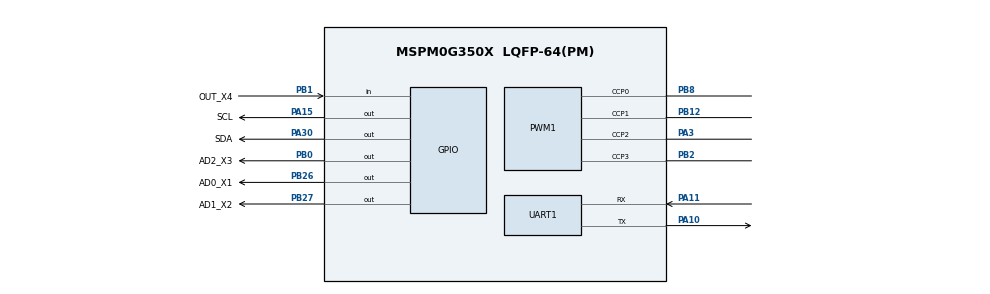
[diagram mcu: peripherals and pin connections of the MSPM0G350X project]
/**
 * @cliArgs --device "MSPM0G350X" --part "Default" --package "LQFP-64(PM)" --product "mspm0_sdk@2.02.00.05"
 * @versions {"tool":"1.21.1+3772"}
 */

/**
 * Import the modules used in this configuration.
 */
const GPIO    = scripting.addModule("/ti/driverlib/GPIO", {}, false);
const GPIO1   = GPIO.addInstance();
const GPIO2   = GPIO.addInstance();
const GPIO3   = GPIO.addInstance();
const GPIO4   = GPIO.addInstance();
const GPIO5   = GPIO.addInstance();
const GPIO6   = GPIO.addInstance();
const PWM     = scripting.addModule("/ti/driverlib/PWM", {}, false);
const PWM1    = PWM.addInstance();
const SYSCTL  = scripting.addModule("/ti/driverlib/SYSCTL");
const SYSTICK = scripting.addModule("/ti/driverlib/SYSTICK");
const TIMER   = scripting.addModule("/ti/driverlib/TIMER", {}, false);
const TIMER1  = TIMER.addInstance();
const TIMER2  = TIMER.addInstance();
const UART    = scripting.addModule("/ti/driverlib/UART", {}, false);
const UART1   = UART.addInstance();

/**
 * Write custom configuration values to the imported modules.
 */
const divider7       = system.clockTree["PLL_PDIV"];
divider7.divideValue = 2;

const divider9       = system.clockTree["UDIV"];
divider9.divideValue = 2;

const gate7  = system.clockTree["MFCLKGATE"];
gate7.enable = true;

const multiplier2         = system.clockTree["PLL_QDIV"];
multiplier2.multiplyValue = 8;

const mux4       = system.clockTree["EXHFMUX"];
mux4.inputSelect = "EXHFMUX_XTAL";

const mux8       = system.clockTree["HSCLKMUX"];
mux8.inputSelect = "HSCLKMUX_SYSPLL0";

const mux12       = system.clockTree["SYSPLLMUX"];
mux12.inputSelect = "zSYSPLLMUX_HFCLK";

const pinFunction4        = system.clockTree["HFXT"];
pinFunction4.inputFreq    = 40;
pinFunction4.enable       = true;
pinFunction4.HFCLKMonitor = true;
pinFunction4.HFXTStartup  = 100;

GPIO1.$name                              = "LED";
GPIO1.port                               = "PORTA";
GPIO1.associatedPins[0].internalResistor = "PULL_DOWN";
GPIO1.associatedPins[0].assignedPin      = "17";
GPIO1.associatedPins[0].$name            = "MCU";

const Board = scripting.addModule("/ti/driverlib/Board", {}, false);

GPIO2.$name                         = "BEEP";
GPIO2.port                          = "PORTB";
GPIO2.associatedPins[0].assignedPin = "5";
GPIO2.associatedPins[0].$name       = "OUT";

GPIO3.$name                          = "OLED";
GPIO3.port                           = "PORTA";
GPIO3.associatedPins.create(2);
GPIO3.associatedPins[0].$name        = "SCL";
GPIO3.associatedPins[0].initialValue = "SET";
GPIO3.associatedPins[0].assignedPin  = "15";
GPIO3.associatedPins[0].pin.$assign  = "PA15";
GPIO3.associatedPins[1].$name        = "SDA";
GPIO3.associatedPins[1].initialValue = "SET";
GPIO3.associatedPins[1].assignedPin  = "30";
GPIO3.associatedPins[1].pin.$assign  = "PA30";

GPIO4.$name                               = "GPIO_ENCODER_L";
GPIO4.associatedPins.create(2);
GPIO4.associatedPins[0].direction         = "INPUT";
GPIO4.associatedPins[0].assignedPort      = "PORTB";
GPIO4.associatedPins[0].$name             = "H1A";
GPIO4.associatedPins[0].assignedPin       = "21";
GPIO4.associatedPins[0].polarity          = "RISE";
GPIO4.associatedPins[0].interruptEn       = true;
GPIO4.associatedPins[0].interruptPriority = "0";
GPIO4.associatedPins[1].direction         = "INPUT";
GPIO4.associatedPins[1].assignedPort      = "PORTB";
GPIO4.associatedPins[1].$name             = "H1B";
GPIO4.associatedPins[1].assignedPin       = "22";
GPIO4.associatedPins[1].polarity          = "RISE";
GPIO4.associatedPins[1].interruptEn       = true;
GPIO4.associatedPins[1].interruptPriority = "0";

GPIO5.$name                               = "GPIO_ENCODER_R";
GPIO5.associatedPins.create(2);
GPIO5.associatedPins[0].$name             = "H2A";
GPIO5.associatedPins[0].direction         = "INPUT";
GPIO5.associatedPins[0].assignedPort      = "PORTB";
GPIO5.associatedPins[0].assignedPin       = "13";
GPIO5.associatedPins[0].polarity          = "RISE";
GPIO5.associatedPins[0].interruptEn       = true;
GPIO5.associatedPins[0].interruptPriority = "0";
GPIO5.associatedPins[1].$name             = "H2B";
GPIO5.associatedPins[1].direction         = "INPUT";
GPIO5.associatedPins[1].assignedPort      = "PORTA";
GPIO5.associatedPins[1].assignedPin       = "31";
GPIO5.associatedPins[1].interruptEn       = true;
GPIO5.associatedPins[1].polarity          = "RISE";
GPIO5.associatedPins[1].interruptPriority = "0";

GPIO6.$name                              = "Eight_IR";
GPIO6.associatedPins.create(4);
GPIO6.associatedPins[0].$name            = "AD0_X1";
GPIO6.associatedPins[0].pin.$assign      = "PB26";
GPIO6.associatedPins[1].$name            = "AD1_X2";
GPIO6.associatedPins[1].pin.$assign      = "PB27";
GPIO6.associatedPins[2].$name            = "AD2_X3";
GPIO6.associatedPins[2].pin.$assign      = "PB0";
GPIO6.associatedPins[3].$name            = "OUT_X4";
GPIO6.associatedPins[3].direction        = "INPUT";
GPIO6.associatedPins[3].internalResistor = "PULL_UP";
GPIO6.associatedPins[3].pin.$assign      = "PB1";

PWM1.$name                              = "motor_PWM";
PWM1.clockDivider                       = 2;
PWM1.ccIndex                            = [0,1,2,3];
PWM1.peripheral.ccp0Pin.$assign         = "PB8";
PWM1.peripheral.ccp1Pin.$assign         = "PB12";
PWM1.peripheral.ccp2Pin.$assign         = "PA3";
PWM1.peripheral.ccp3Pin.$assign         = "PB2";
PWM1.PWM_CHANNEL_0.$name                = "ti_driverlib_pwm_PWMTimerCC0";
PWM1.PWM_CHANNEL_1.$name                = "ti_driverlib_pwm_PWMTimerCC1";
PWM1.ccp0PinConfig.direction            = scripting.forceWrite("OUTPUT");
PWM1.ccp0PinConfig.hideOutputInversion  = scripting.forceWrite(false);
PWM1.ccp0PinConfig.onlyInternalResistor = scripting.forceWrite(false);
PWM1.ccp0PinConfig.passedPeripheralType = scripting.forceWrite("Digital");
PWM1.ccp0PinConfig.$name                = "ti_driverlib_gpio_GPIOPinGeneric2";
PWM1.ccp1PinConfig.direction            = scripting.forceWrite("OUTPUT");
PWM1.ccp1PinConfig.hideOutputInversion  = scripting.forceWrite(false);
PWM1.ccp1PinConfig.onlyInternalResistor = scripting.forceWrite(false);
PWM1.ccp1PinConfig.passedPeripheralType = scripting.forceWrite("Digital");
PWM1.ccp1PinConfig.$name                = "ti_driverlib_gpio_GPIOPinGeneric3";
PWM1.PWM_CHANNEL_2.$name                = "ti_driverlib_pwm_PWMTimerCC2";
PWM1.PWM_CHANNEL_3.$name                = "ti_driverlib_pwm_PWMTimerCC3";
PWM1.ccp2PinConfig.$name                = "ti_driverlib_gpio_GPIOPinGeneric4";
PWM1.ccp3PinConfig.$name                = "ti_driverlib_gpio_GPIOPinGeneric5";

SYSCTL.forceDefaultClkConfig = true;
SYSCTL.clockTreeEn           = true;
SYSCTL.validateClkStatus     = true;

SYSTICK.periodEnable      = true;
SYSTICK.systickEnable     = true;
SYSTICK.interruptPriority = "0";
SYSTICK.period            = 80;

TIMER1.$name              = "TIMER_20ms";
TIMER1.timerPeriod        = "20 ms";
TIMER1.timerClkDiv        = 8;
TIMER1.timerClkPrescale   = 10;
TIMER1.timerMode          = "PERIODIC";
TIMER1.interrupts         = ["ZERO"];
TIMER1.interruptPriority  = "1";
TIMER1.peripheral.$assign = "TIMG6";

TIMER2.$name              = "TIMER_DISPLAY";
TIMER2.timerMode          = "PERIODIC";
TIMER2.timerClkDiv        = 8;
TIMER2.timerClkPrescale   = 125;
TIMER2.interrupts         = ["ZERO"];
TIMER2.interruptPriority  = "2";
TIMER2.timerPeriod        = "50ms";
TIMER2.peripheral.$assign = "TIMA1";

UART1.$name                    = "UART_0";
UART1.targetBaudRate           = 115200;
UART1.enabledInterrupts        = ["RX","RX_TIMEOUT_ERROR"];
UART1.rxFifoThreshold          = "DL_UART_RX_FIFO_LEVEL_ONE_ENTRY";
UART1.rxTimeoutValue           = 15;
UART1.uartClkDiv               = "4";
UART1.peripheral.$assign       = "UART0";
UART1.peripheral.rxPin.$assign = "PA11";
UART1.peripheral.txPin.$assign = "PA10";
UART1.txPinConfig.$name        = "ti_driverlib_gpio_GPIOPinGeneric0";
UART1.rxPinConfig.$name        = "ti_driverlib_gpio_GPIOPinGeneric1";

/**
 * Pinmux solution for unlocked pins/peripherals. This ensures that minor changes to the automatic solver in a future
 * version of the tool will not impact the pinmux you originally saw.  These lines can be completely deleted in order to
 * re-solve from scratch.
 */
pinFunction4.peripheral.$suggestSolution           = "SYSCTL";
pinFunction4.peripheral.hfxInPin.$suggestSolution  = "PA5";
pinFunction4.peripheral.hfxOutPin.$suggestSolution = "PA6";
GPIO1.associatedPins[0].pin.$suggestSolution       = "PA17";
Board.peripheral.$suggestSolution                  = "DEBUGSS";
Board.peripheral.swclkPin.$suggestSolution         = "PA20";
Board.peripheral.swdioPin.$suggestSolution         = "PA19";
GPIO2.associatedPins[0].pin.$suggestSolution       = "PB5";
GPIO4.associatedPins[0].pin.$suggestSolution       = "PB21";
GPIO4.associatedPins[1].pin.$suggestSolution       = "PB22";
GPIO5.associatedPins[0].pin.$suggestSolution       = "PB13";
GPIO5.associatedPins[1].pin.$suggestSolution       = "PA31";
PWM1.peripheral.$suggestSolution                   = "TIMA0";
